# cpsw_9xuss_j7am0_CPSW_NUSS_VBUSP register map
Vendor: Texas Instruments
Registers are 32-bit, read-write, reset 0x0 unless marked. A register's access mark holds for its fields unless they carry their own. Offsets are as the file gives them; [hi:lo] are bit positions; lines under a group give offsets from that group; {n}, {i} and the like mark numbered series; 'fields as' and 'values as' point back to an identical list.

## cpsw_9xuss_j7am0_CPSW_NUSS_VBUSP (part 2 of 3)
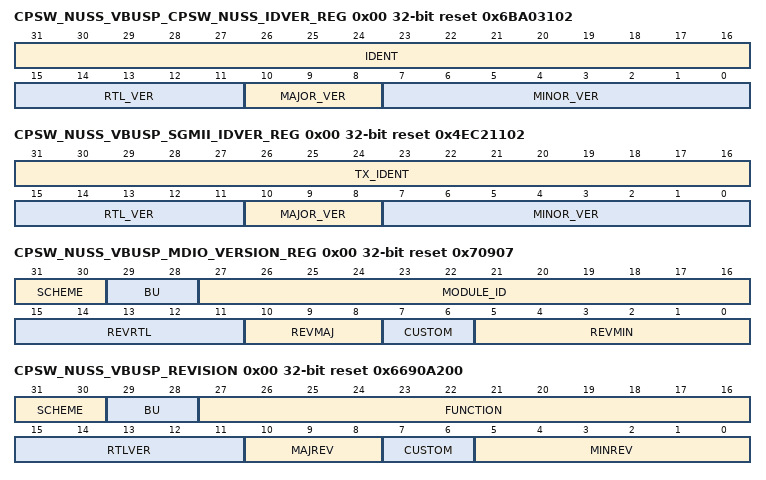
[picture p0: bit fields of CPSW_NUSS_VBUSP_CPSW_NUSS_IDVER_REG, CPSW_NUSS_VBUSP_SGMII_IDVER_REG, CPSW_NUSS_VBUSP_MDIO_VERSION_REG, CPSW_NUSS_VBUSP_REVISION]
0x00 CPSW_NUSS_VBUSP_CPSW_NUSS_IDVER_REG ro reset 0x6BA03102
  [31:16] IDENT — Identification value
  [15:11] RTL_VER — RTL version value
  [10:8] MAJOR_VER — Major version value
  [7:0] MINOR_VER — Minor version value
0x00 CPSW_NUSS_VBUSP_SGMII_IDVER_REG ro reset 0x4EC21102
  [31:16] TX_IDENT — MODULE value
  [15:11] RTL_VER — RTL version value
  [10:8] MAJOR_VER — Major version value
  [7:0] MINOR_VER — Minor version value
0x00 CPSW_NUSS_VBUSP_MDIO_VERSION_REG ro reset 0x70907
  [31:30] SCHEME
  [29:28] BU
  [27:16] MODULE_ID
  [15:11] REVRTL — RTL version
  [10:8] REVMAJ — Major version
  [7:6] CUSTOM — Custom version
  [5:0] REVMIN — Minor version
0x00 CPSW_NUSS_VBUSP_REVISION ro reset 0x6690A200
  [31:30] SCHEME
  [29:28] BU
  [27:16] FUNCTION — Module ID
  [15:11] RTLVER — RTL revisions
  [10:8] MAJREV — Major revision
  [7:6] CUSTOM — Custom revision
  [5:0] MINREV — Minor revision
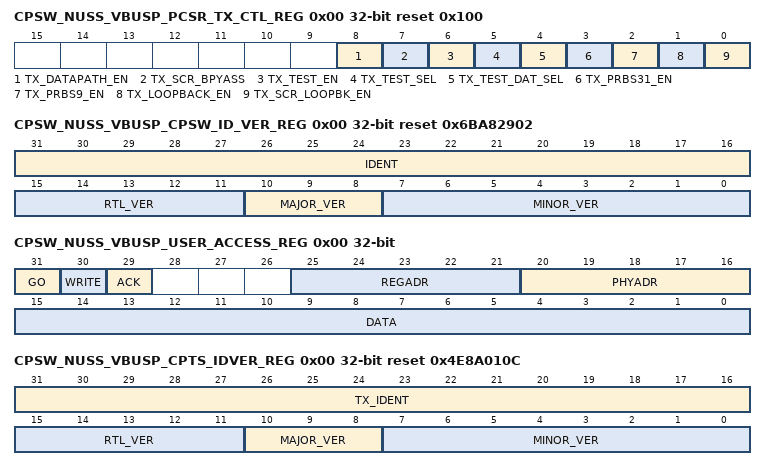
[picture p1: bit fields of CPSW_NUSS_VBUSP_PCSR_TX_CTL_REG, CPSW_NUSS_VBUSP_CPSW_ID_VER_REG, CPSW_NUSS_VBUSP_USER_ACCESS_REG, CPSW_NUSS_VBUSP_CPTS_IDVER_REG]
0x00 CPSW_NUSS_VBUSP_PCSR_TX_CTL_REG reset 0x100
  [8] TX_DATAPATH_EN — PCSR Transmit Datapath Enable
  [7] TX_SCR_BPYASS — PCSR Transmit SCR Bypass
  [6] TX_TEST_EN — PCSR Transmit Test Enable
  [5] TX_TEST_SEL — PCSR Transmit Test Select
  [4] TX_TEST_DAT_SEL — PCSR Transmit Test Data Select
  [3] TX_PRBS31_EN — PCSR Transmit PRBS31 Enable
  [2] TX_PRBS9_EN — PCSR Transmit PRBS9 Enable
  [1] TX_LOOPBACK_EN — PCSR Transmit Loopback Enable
  [0] TX_SCR_LOOPBK_EN — PCSR Transmit SCR Loopback Enable
0x00 CPSW_NUSS_VBUSP_CPSW_ID_VER_REG ro reset 0x6BA82902
  [31:16] IDENT — Identification Value
  [15:11] RTL_VER — RTL Version Value
  [10:8] MAJOR_VER — Major Version Value
  [7:0] MINOR_VER — Minor Version Value
0x00 CPSW_NUSS_VBUSP_USER_ACCESS_REG
  [31] GO
  [30] WRITE
  [29] ACK — Acknowledge
  [25:21] REGADR — Register address
  [20:16] PHYADR — PHY address
  [15:0] DATA — User data
0x00 CPSW_NUSS_VBUSP_PN_RESERVED_REG ro
0x00 CPSW_NUSS_VBUSP_PN_RESERVED_REG ro
0x00 CPSW_NUSS_VBUSP_PN_RESERVED_REG ro
0x00 CPSW_NUSS_VBUSP_PN_RESERVED_REG ro
0x00 CPSW_NUSS_VBUSP_PN_RESERVED_REG ro
0x00 CPSW_NUSS_VBUSP_PN_RESERVED_REG ro
0x00 CPSW_NUSS_VBUSP_PN_RESERVED_REG ro
0x00 CPSW_NUSS_VBUSP_PN_RESERVED_REG ro
0x00 CPSW_NUSS_VBUSP_FETCH_LOC
  [21:0] LOC — RAM Location
0x00 CPSW_NUSS_VBUSP_RXGOODFRAMES
  [31:0] COUNT — Total number of good frames received
0x00 CPSW_NUSS_VBUSP_CPTS_IDVER_REG ro reset 0x4E8A010C
  [31:16] TX_IDENT — Identification value
  [15:11] RTL_VER — RTL version value
  [10:8] MAJOR_VER — Major version value
  [7:0] MINOR_VER — Minor version value
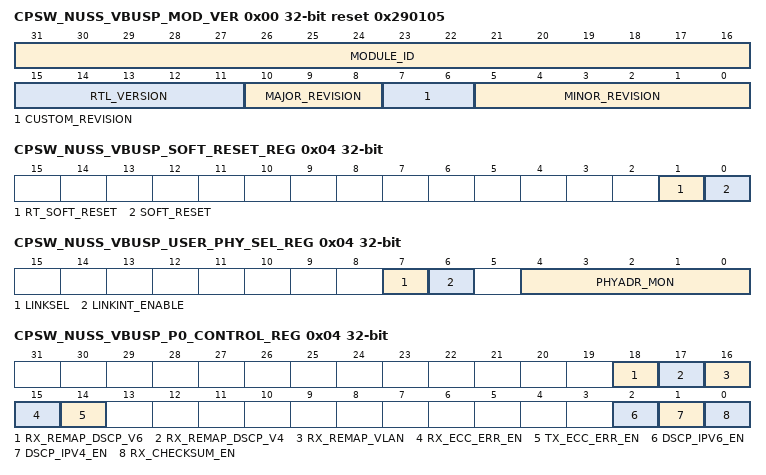
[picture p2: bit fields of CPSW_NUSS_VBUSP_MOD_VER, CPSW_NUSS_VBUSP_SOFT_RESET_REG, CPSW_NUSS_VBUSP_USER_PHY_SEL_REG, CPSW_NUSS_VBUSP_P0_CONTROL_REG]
0x00 CPSW_NUSS_VBUSP_MOD_VER ro reset 0x290105
  [31:16] MODULE_ID — ALE_9g2x1ie module ID.
  [15:11] RTL_VERSION
  [10:8] MAJOR_REVISION
  [7:6] CUSTOM_REVISION
  [5:0] MINOR_REVISION
0x00 CPSW_NUSS_VBUSP_COMP_LOW_REG
  [31:0] COMP_LOW — Time Stamp Generate Function Comparison Low Value
0x00 CPSW_NUSS_VBUSP_COMP_LOW_REG
  [31:0] COMP_LOW — Time Stamp ESTF Generate Function Comparison Low Value
0x04 CPSW_NUSS_VBUSP_SYNCE_COUNT_REG
  [31:0] SYNCE_CNT — Sync E Count Value
0x04 CPSW_NUSS_VBUSP_SOFT_RESET_REG
  [1] RT_SOFT_RESET — Transmit and receive software reset
  [0] SOFT_RESET — Software reset
0x04 CPSW_NUSS_VBUSP_CONTROL_REG access per field reset 0x810000FF
  [31] IDLE ro — MDIO state machine idle
  [30] ENABLE rw — Enable control
  [28:24] HIGHEST_USER_CHANNEL ro
  [20] PREAMBLE rw — Preamble disable
  [19] FAULT rw — Fault indicator
  [18] FAULT_DETECT_ENABLE rw
  [17] INT_TEST_ENABLE rw — Interrupt test enable
  [15:0] CLKDIV rw — Clock divider
0x04 CPSW_NUSS_VBUSP_PCSR_TX_STATUS_REG access not given
  [8] TX_FAULT — PCSR Transmit Fault Hold Register - write 1 to clear (access R/WC)
0x04 CPSW_NUSS_VBUSP_CONTROL_REG
  [31] ECC_CRC_MODE
  [18] EST_ENABLE — Intersperced Express Traffic enable
  [17] IET_ENABLE — Intersperced Express Traffic enable
  [16] EEE_ENABLE — Energy Efficient Ethernet enable
  [15] P0_RX_PASS_CRC_ERR — Port 0 Pass Received CRC errors
  [14] P0_RX_PAD — Port 0 Receive Short Packet Pad
  [13] P0_TX_CRC_REMOVE — Port 0 Transmit CRC remove
  [12] P0_TX_CRC_TYPE — Port 0 Transmit CRC Type
  [n+3] P{n}_PASS_PRI_TAGGED (n=0..8) — Port {n} Pass Priority Tagged
  [2] P0_ENABLE — Port 0 Enable
  [1] VLAN_AWARE — VLAN Aware Mode
  [0] S_CN_SWITCH — VLAN Aware Mode
0x04 CPSW_NUSS_VBUSP_USER_PHY_SEL_REG
  [7] LINKSEL — Link status determination select
  [6] LINKINT_ENABLE — Link change interrupt enable
  [4:0] PHYADR_MON — PHY address whose link status is monitored
0x04 CPSW_NUSS_VBUSP_P0_CONTROL_REG
  [18] RX_REMAP_DSCP_V6 — Port 0 Remap DSCP_V6 Enable
  [17] RX_REMAP_DSCP_V4 — Port 0 Remap DSCP_V4 Enable
  [16] RX_REMAP_VLAN — Port 0 Remap VLAN Enable
  [15] RX_ECC_ERR_EN — Port 0 Receive ECC Error Enable
  [14] TX_ECC_ERR_EN — Port 0 Transmit ECC Error Enable
  [2] DSCP_IPV6_EN — Port 0 IPv6 DSCP enable
  [1] DSCP_IPV4_EN — Port 0 IPv4 DSCP enable
  [0] RX_CHECKSUM_EN — Port 0 Receive Checksum Enable
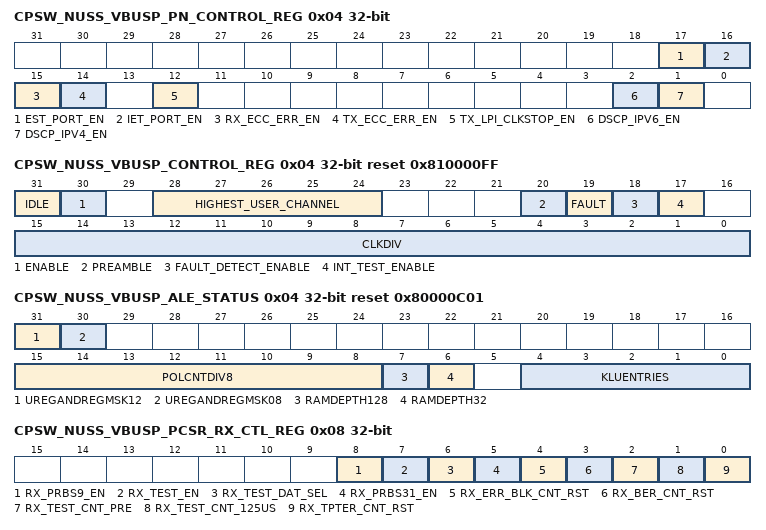
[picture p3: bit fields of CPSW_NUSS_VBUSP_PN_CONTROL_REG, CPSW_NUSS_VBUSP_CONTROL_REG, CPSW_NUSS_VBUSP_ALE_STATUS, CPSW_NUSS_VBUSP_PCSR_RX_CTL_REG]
0x04 CPSW_NUSS_VBUSP_PN_CONTROL_REG
  [17] EST_PORT_EN — EST Port Enable
  [16] IET_PORT_EN — IET Port Enable
  [15] RX_ECC_ERR_EN — Port 0 Receive ECC Error Enable
  [14] TX_ECC_ERR_EN — Port 0 Transmit ECC Error Enable
  [12] TX_LPI_CLKSTOP_EN — Transmit LPI clockstop enable
  [2] DSCP_IPV6_EN — IPv6 DSCP enable
  [1] DSCP_IPV4_EN — IPv4 DSCP enable
0x04 CPSW_NUSS_VBUSP_PN_CONTROL_REG
  fields as CPSW_NUSS_VBUSP_PN_CONTROL_REG
0x04 CPSW_NUSS_VBUSP_PN_CONTROL_REG
  fields as CPSW_NUSS_VBUSP_PN_CONTROL_REG
0x04 CPSW_NUSS_VBUSP_PN_CONTROL_REG
  fields as CPSW_NUSS_VBUSP_PN_CONTROL_REG
0x04 CPSW_NUSS_VBUSP_PN_CONTROL_REG
  fields as CPSW_NUSS_VBUSP_PN_CONTROL_REG
0x04 CPSW_NUSS_VBUSP_PN_CONTROL_REG
  fields as CPSW_NUSS_VBUSP_PN_CONTROL_REG
0x04 CPSW_NUSS_VBUSP_PN_CONTROL_REG
  fields as CPSW_NUSS_VBUSP_PN_CONTROL_REG
0x04 CPSW_NUSS_VBUSP_PN_CONTROL_REG
  fields as CPSW_NUSS_VBUSP_PN_CONTROL_REG
0x04 CPSW_NUSS_VBUSP_RXBROADCASTFRAMES
  [31:0] COUNT — Total number of good broadcast frames received
0x04 CPSW_NUSS_VBUSP_CONTROL_REG reset 0x4
  [31:28] TS_SYNC_SEL — TS_SYNC output timestamp counter bit select
  [17] TS_GENF_CLR_EN — Enable for GENF clear when length is zero
  [16] TS_RX_NO_EVENT — Receive Produces no Events
  [n+7] HW{n}_TS_PUSH_EN (n=1..8) — Hardware push {n} enable
  [7] TS_PPM_DIR — Timestamp PPM Direction
  [6] TS_COMP_TOG — Timestamp Compare Toggle mode: 0=TS_COMP is in non-toggle mode, 1=TS_COMP is in toggle mode
  [5] MODE — Timestamp mode
  [4] SEQUENCE_EN — Sequence Enable
  [3] TSTAMP_EN — Host Receive Timestamp Enable
  [2] TS_COMP_POLARITY
  [1] INT_TEST — Interrupt test
  [0] CPTS_EN — Time sync enable
0x04 CPSW_NUSS_VBUSP_ALE_STATUS ro reset 0x80000C01
  [31] UREGANDREGMSK12 — When set, the unregistered multicast field is a mask versus an index on 12 bit boundary in the ALE table.
  [30] UREGANDREGMSK08 — When set, the unregistered multicast field is a mask versus an index on 8 bit boundary in the ALE table.
  [15:8] POLCNTDIV8 — This is the number of Classifiers the ALE implements divided by 8. A value of 4 indicates 32 policer engines total.
  [7] RAMDEPTH128 — The number of ALE entries per slice of the table when this is set it indicates the depth is 128 if both ramdepth128 and ramdepth32 are zero the depth is 64.
  [6] RAMDEPTH32 — The number of ALE entries per slice of the table when this is set it indicates the depth is 32 if both ramdepth128 and ramdepth32 are zero the depth is 64.
  [4:0] KLUENTRIES — This is the number of table entries total divided by 1024. A value of 1 indicates 1024 table entries. A value of 8 indicates 8192 table entries.
0x04 CPSW_NUSS_VBUSP_COMP_HIGH_REG
  [31:0] COMP_HIGH — Time Stamp Generate Function Comparison High Value
0x04 CPSW_NUSS_VBUSP_COMP_HIGH_REG
  [31:0] COMP_HIGH — Time Stamp ESTF Generate Function Comparison High Value
0x08 CPSW_NUSS_VBUSP_SYNCE_MUX_REG
  [5:0] SYNCE_SEL — Sync E Select Value
0x08 CPSW_NUSS_VBUSP_ALIVE_REG
  [31:0] ALIVE — MDIO alive
0x08 CPSW_NUSS_VBUSP_PCSR_RX_CTL_REG
  [8] RX_PRBS9_EN — PCSR Receive PRBS9 Enable
  [7] RX_TEST_EN — PCSR Receive Test Enable
  [6] RX_TEST_DAT_SEL — PCSR Receive Test Data Select
  [5] RX_PRBS31_EN — PCSR Receive PRBS31 Enable
  [4] RX_ERR_BLK_CNT_RST — PCSR Receive Error Block Count Reset
  [3] RX_BER_CNT_RST — PCSR Receive BER Count Reset
  [2] RX_TEST_CNT_PRE — PCSR Receive Test Count Pre
  [1] RX_TEST_CNT_125US — PCSR Receive Test Count 125us
  [0] RX_TPTER_CNT_RST — PCSR Receive TPTER Count Reset
0x08 CPSW_NUSS_VBUSP_P0_FLOW_ID_OFFSET_REG
  [13:0] VALUE — This value is added to the thread/Flow_ID in CPPI transmit PSI Info Word 0
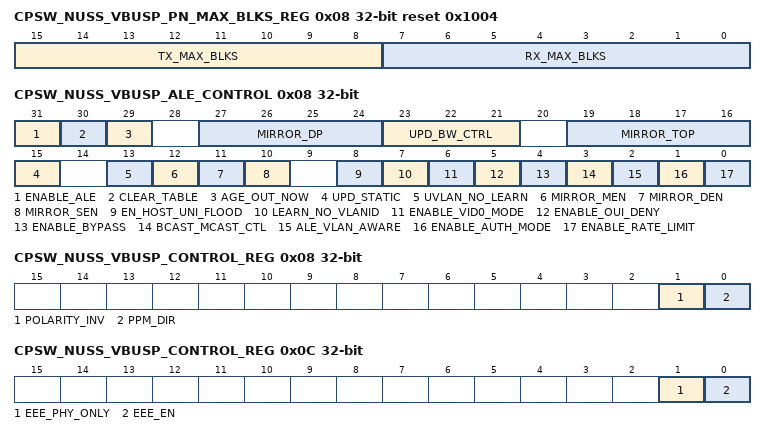
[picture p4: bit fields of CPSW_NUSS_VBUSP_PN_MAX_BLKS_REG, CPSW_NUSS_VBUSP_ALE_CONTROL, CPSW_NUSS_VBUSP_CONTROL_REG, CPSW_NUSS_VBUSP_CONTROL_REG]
0x08 CPSW_NUSS_VBUSP_PN_MAX_BLKS_REG reset 0x1004
  [15:8] TX_MAX_BLKS — Transmit FIFO maximum blocks
  [7:0] RX_MAX_BLKS — Receive FIFO maximum blocks
0x08 CPSW_NUSS_VBUSP_PN_MAX_BLKS_REG reset 0x1004
  fields as CPSW_NUSS_VBUSP_PN_MAX_BLKS_REG
0x08 CPSW_NUSS_VBUSP_PN_MAX_BLKS_REG reset 0x1004
  fields as CPSW_NUSS_VBUSP_PN_MAX_BLKS_REG
0x08 CPSW_NUSS_VBUSP_PN_MAX_BLKS_REG reset 0x1004
  fields as CPSW_NUSS_VBUSP_PN_MAX_BLKS_REG
0x08 CPSW_NUSS_VBUSP_PN_MAX_BLKS_REG reset 0x1004
  fields as CPSW_NUSS_VBUSP_PN_MAX_BLKS_REG
0x08 CPSW_NUSS_VBUSP_PN_MAX_BLKS_REG reset 0x1004
  fields as CPSW_NUSS_VBUSP_PN_MAX_BLKS_REG
0x08 CPSW_NUSS_VBUSP_PN_MAX_BLKS_REG reset 0x1004
  fields as CPSW_NUSS_VBUSP_PN_MAX_BLKS_REG
0x08 CPSW_NUSS_VBUSP_PN_MAX_BLKS_REG reset 0x1004
  fields as CPSW_NUSS_VBUSP_PN_MAX_BLKS_REG
0x08 CPSW_NUSS_VBUSP_RXMULTICASTFRAMES
  [31:0] COUNT — Total number of good multicast frames received
0x08 CPSW_NUSS_VBUSP_RFTCLK_SEL_REG
  [4:0] RFTCLK_SEL — Reference clock select
0x08 CPSW_NUSS_VBUSP_ALE_CONTROL
  [31] ENABLE_ALE — Enable ALE 0 - Drop all packets 1 - Enable ALE packet processing
  [30] CLEAR_TABLE — Clear ALE address table - Setting this bit causes the ALE hardware to write all table bit values to zero. Software must perform a clear table operation as part of the ALE setup/configuration process. Setting this bit causes all ALE accesses to be held up for 64 clocks while the clear is performed. Access to all ALE registers will be blocked (wait states) until the 64 clocks have completed. This bit cannot be read as one because the read is blocked until the clear table is completed at which time this bit is cleared to zero.
  [29] AGE_OUT_NOW — Age Out Address Table Now - Setting this bit causes the ALE hardware to remove (free up) any ageable table entry that does not have a set touch bit. This bit is cleared when the age out process has completed. This bit may be read. The age out process takes four times the number of table entries clock cycles (4096 cycles for 1K addresses) best case (no ale packet processing during ageout) and sixty five times the number of table entries clock cycles (66560 cycles for 1K addresses) absolute worst case.
  [27:24] MIRROR_DP — Mirror Destination Port - This field defines the port to which destination traffic destined will be duplicated. That is all traffic that is forwarded to this port will also be mirrored to the ~imirror_top port.
  [23:21] UPD_BW_CTRL — The ~iupd_bw_ctrl field allows for up to 8 times the rate in which adds, updates, touches, writes, and aging updates can occur. At frequencies of 350Mhz, the table update rate should be at it lowest or 5 Million updates per second. When operating the switch core at frequencies or above, the ~iupd_bw_ctrl can be programmed more aggressive. If the ~iupd_bw_ctrl is set but the frequency of the switch subsystem is below the associated value, ALE will drop packets due to insufficient time to complete lookup under high traffic loads. 0 - 350Mhz, 5M 1 - 359Mhz, 11M 2 - 367Mhz, 16M 3 - 375Mhz, 22M 4 - 384Mhz, 28M 5 - 392Mhz, 34M 6 - 400Mhz, 39M 7 - 409Mhz, 45M
  [19:16] MIRROR_TOP — Mirror To Port - This field defines the destination port for the mirror traffic. If the traffic is received or transmitted on the mirror destination port it will not be duplicated. Traffic defined as mirror traffic only may be dropped by the switch due to congestion.
  [15] UPD_STATIC — Update Static Entries - A static Entry is an entry that is not agable. When clear this bit will prevent any static entry (agable bit clear) from being updated due to port change. When set it allows static entries (agable bit clear) to update the source port if required. This bit should normally be '0' for most switch configurations.
  [13] UVLAN_NO_LEARN — Unknown VLAN No Learn - This field when set will prevent source addresses of unknown VLAN IDs from being automatically added into the look up table if learning is enabled.
  [12] MIRROR_MEN — Mirror Match Entry Enable - This field enables the match mirror option. When this bit is set any traffic whose destination, source, VLAN or OUI matches the ~imirror_midx entry index will have that traffic also sent to the ~imirror_top port.
  [11] MIRROR_DEN — Mirror Destination Port Enable - This field enables the destination port mirror option. When this bit is set any traffic destined for the ~imirror_dp port will have its transmit traffic also sent to the ~imirror_top port.
  [10] MIRROR_SEN — Mirror Source Port Enable - This field enables the source port mirror option. When this bit is set any port with the ~ipX_mirror_sp set in the ALE Port Control registers set will have its received traffic also sent to the ~imirror_top port.
  [8] EN_HOST_UNI_FLOOD — Unknown unicast packets flood to host 0 - unknown unicast packets are not sent to the host 1 - unknown unicast packets flood to host port as well as other ports
  [7] LEARN_NO_VLANID — Learn No VID - 0 - VID is learned with the source address 1 - VID is not learned with the source address (source address is not tied to VID). Determines the entry type.
  [6] ENABLE_VID0_MODE — Enable VLAN ID = 0 Mode 0 - Process the priority tagged packet with VID = PORT_VLAN[11:0]. 1 - Process the priority tagged packet with VID = 0.
  [5] ENABLE_OUI_DENY — Enable OUI Deny Mode - When set, any packet with a non-matching OUI source address will be dropped to the host unless the packet destination address matches a supervisory destination address table entry. When cleared, any packet source address matching an OUI address table entry will be dropped to the host unless the destination address matches with a supervisory destination address table entry.
  [4] ENABLE_BYPASS — ALE Bypass - When set, packets received on non-host ports are sent to the host. It is expected that packets from the host are directed to the particular port. 0 - no bypass 1 - bypass the ALE
  [3] BCAST_MCAST_CTL — Rate Limit Transmit mode 0 - Broadcast and multicast rate limit counters are received port based 1 - Broadcast and multicast rate limit counters are transmit port based
  [2] ALE_VLAN_AWARE — ALE VLAN Aware - Determines how traffic is forwarded using VLAN rules. 0 - Simple switch rules, packets forwarded to all ports for unknown destinations. 1 - VLAN Aware rules, packets forwarded based on VLAN members
  [1] ENABLE_AUTH_MODE — Enable MAC Authorization Mode - Mac authorization mode requires that all table entries be made by the host software. There is no auto learning of addresses in authorization mode and the packet will be dropped if the source address is not found (and the destination address is not a multicast address with the super table entry bit set). 0 - The ALE is not in MAC authorization mode 1 - The ALE is in MAC authorization mode
  [0] ENABLE_RATE_LIMIT — Enable Broadcast and Multicast Rate Limit 0 - Broadcast/Multicast rates not limited 1 - Broadcast/Multicast packet reception limited to the port control register rate limit fields.
0x08 CPSW_NUSS_VBUSP_CONTROL_REG
  [1] POLARITY_INV — Time Stamp Generate Function Polarity Invert
  [0] PPM_DIR — Time Stamp Generate Function PPM Direction
0x08 CPSW_NUSS_VBUSP_CONTROL_REG
  [1] POLARITY_INV — Time Stamp ESTF Generate Function Polarity Invert
  [0] PPM_DIR — Time Stamp ESTF Generate Function PPM Direction
0x0C CPSW_NUSS_VBUSP_CONTROL_REG
  [1] EEE_PHY_ONLY — Energy Efficient Enable Phy Only Mode: 0=The low power indicate state includes gating off the CPPI_GCLK to the CPSW, 1=The low power indicate state does not gate the clock to the CPSW
  [0] EEE_EN — Energy Efficient Ethernet Enable: 0=EEE is disabled, 1=EEE is enabled
0x0C CPSW_NUSS_VBUSP_LINK_REG ro
  [31:0] LINK — MDIO link state
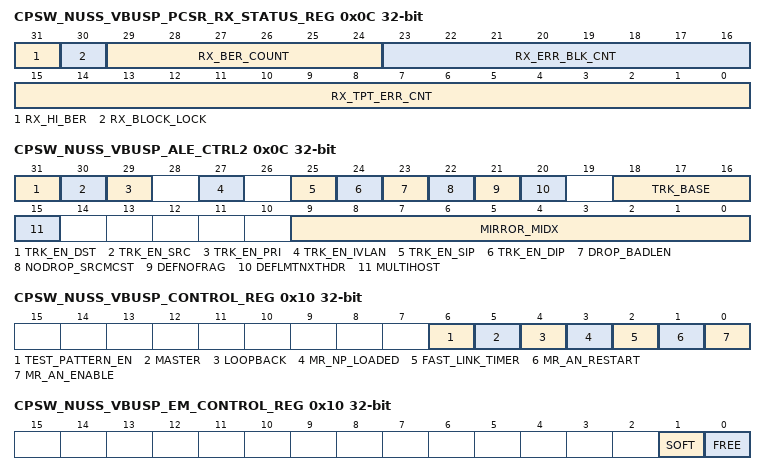
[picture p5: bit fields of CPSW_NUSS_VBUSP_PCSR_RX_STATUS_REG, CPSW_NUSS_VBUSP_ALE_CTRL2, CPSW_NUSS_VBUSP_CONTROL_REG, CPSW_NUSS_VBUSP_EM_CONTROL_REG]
0x0C CPSW_NUSS_VBUSP_PCSR_RX_STATUS_REG ro
  [31] RX_HI_BER — PCSR Receive High BER
  [30] RX_BLOCK_LOCK — PCSR Receive Block Lock
  [29:24] RX_BER_COUNT — PCSR Receive BER Count
  [23:16] RX_ERR_BLK_CNT — PCSR Error Block Count
  [15:0] RX_TPT_ERR_CNT — PCSR TPT Error Count
0x0C CPSW_NUSS_VBUSP_RXPAUSEFRAMES
  [31:0] COUNT — Total number of pause frames received
0x0C CPSW_NUSS_VBUSP_TS_PUSH_REG wo
  [0] TS_PUSH — Time stamp event push
0x0C CPSW_NUSS_VBUSP_ALE_CTRL2
  [31] TRK_EN_DST — Trunk Enable Destination Address - This field enables the destination MAC address to be used with the hash function G(X) = 1 + X + X^3 and affect the trunk port transmit link determination.
  [30] TRK_EN_SRC — Trunk Enable Source Address - This field enables the source MAC address to be used with the hash function G(X) = 1 + X + X^3 and affect the trunk port transmit link determination.
  [29] TRK_EN_PRI — Trunk Enable Priority - This field enables the VLAN Priority bits to be used with the hash function G(X) = 1 + X + X^3 and affect the trunk port transmit link determination. In the event that DSCP mapping is enabled and there is no VLAN the DSCP priority will be used. For all other non IP frames without VLAN the port default priority is used.
  [27] TRK_EN_IVLAN — Trunk Enable Inner VLAN - This field enables the inner VLAN ID value (C-VLANID) to be used with the hash function G(X) = 1 + X + X^3 and affect the trunk port transmit link determination.
  [25] TRK_EN_SIP — Trunk Enable Source IP Address - This field enables the source IP address to be used with the hash function G(X) = 1 + X + X^3 and affect the trunk port transmit link determination. This feature supports No tag, Priority tagged, VLAN tagged, Q-in-Q double tagging for both IPV6 and IPV4.
  [24] TRK_EN_DIP — Trunk Enable Destination IP Address - This field enables the destination IP address to be used with the hash function G(X) = 1 + X + X^3 and affect the trunk port transmit link determination. This feature supports No tag, Priority tagged, VLAN tagged, Q-in-Q double tagging for both IPV6 and IPV4.
  [23] DROP_BADLEN — Drop Bad Length will drop any packet that the 802.3 length field is larger than the packet. Ethertypes 0-1500 are 802.3 lengths, all others are Ether types.
  [22] NODROP_SRCMCST — No Drop Source Multicast will disable the dropping of any source address with the multicast bit set.
  [21] DEFNOFRAG — Default No Frag field will cause an IPv4 fragmented packet to be dropped if a VLAN entry is not found.
  [20] DEFLMTNXTHDR — Default limit next header field will cause an IPv4 protocol or IPv6 next header packet to be dropped if a VLAN entry is not found and the protocol or next header does not match the ~iALE_NXT_HDR register values.
  [18:16] TRK_BASE — Trunk Base - This field is the hash formula starting value. Changing this value will cause the packet distribution on trunk ports to be changed. If all the ~itrk_en_dst, ~itrk_en_src, ~itrk_en_pri and ~itrk_en_vlan are '0', this value is used as the distribution index. That is a '0' will select the 1st bit of an 'N' link trunk, a '1' will select the second, etc. Below is the distribution across the trunk links. The first number in the ~iitalic sequence indicates the traffic is sent to the lowest numbered port of a trunk group. For example if you have a 3 port trunk, the hash result 0 will go to the base port (0), hash result 1 will go to the highest port of the trunk group (2), hash result 2 will go to the middle port (1), etc. 1 - ~i00000000 2 - ~i01010101 3 - ~i02102102 4 - ~i03210321
  [15] MULTIHOST — The ~multihost allows host traffic to be sent bact to the host if the DA is market for the host port.
  [9:0] MIRROR_MIDX — Mirror Index - This field is the ALE lookup table entry index that when a match occurs will cause this traffic to be mirrored to the ~imirror_top port. That is any VLAN, ONU or address with or withou VLAN can be selected for traffic mirroring.
0x0C CPSW_NUSS_VBUSP_LENGTH_REG
  [31:0] LENGTH — Time Stamp Generate Function Length Value
0x0C CPSW_NUSS_VBUSP_LENGTH_REG
  [31:0] LENGTH — Time Stamp ESTF Generate Function Length Value
0x10 CPSW_NUSS_VBUSP_SGMII_NON_FIBER_MODE_REG reset 0xFF
  [7:0] SGMII_NON_FIBER_MODE — This register bit goes to the CPSGMII mode input only
0x10 CPSW_NUSS_VBUSP_CONTROL_REG
  [6] TEST_PATTERN_EN — Test pattern enable
  [5] MASTER — Master mode
  [4] LOOPBACK — Loopback mode
  [3] MR_NP_LOADED — Next page loaded
  [2] FAST_LINK_TIMER
  [1] MR_AN_RESTART — Auto-negotiation restart
  [0] MR_AN_ENABLE — Auto-negotiation enable
0x10 CPSW_NUSS_VBUSP_LINK_INT_RAW_REG
  [1:0] LINKINTRAW — MDIO link change event raw value
0x10 CPSW_NUSS_VBUSP_eoi_reg
  [7:0] EOI_VECTOR — End of Interrupt Vector
0x10 CPSW_NUSS_VBUSP_PCSR_SEED_A_LO_REG
  [31:0] SEED_A_LO — PCSR Seed A Low
0x10 CPSW_NUSS_VBUSP_EM_CONTROL_REG
  [1] SOFT — Emulation Soft Bit
  [0] FREE — Emulation Free Bit
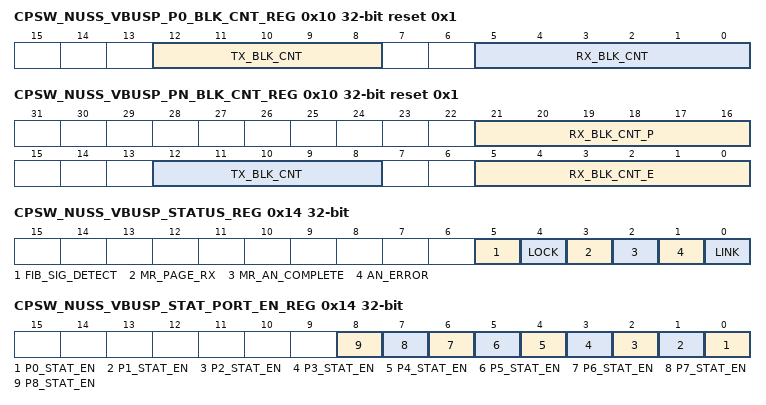
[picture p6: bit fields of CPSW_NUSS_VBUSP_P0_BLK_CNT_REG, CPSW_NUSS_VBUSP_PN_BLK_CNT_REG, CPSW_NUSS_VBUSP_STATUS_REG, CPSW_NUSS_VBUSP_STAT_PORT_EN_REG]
0x10 CPSW_NUSS_VBUSP_P0_BLK_CNT_REG ro reset 0x1
  [12:8] TX_BLK_CNT — Port 0 Transmit Block Count Usage
  [5:0] RX_BLK_CNT — Port 0 Receive Block Count Usage
0x10 CPSW_NUSS_VBUSP_PN_BLK_CNT_REG ro reset 0x1
  [21:16] RX_BLK_CNT_P — Receive Prempt Queue Block Count Usage
  [12:8] TX_BLK_CNT — Transmit Block Count Usage
  [5:0] RX_BLK_CNT_E — Receive Block Count Usage
0x10 CPSW_NUSS_VBUSP_PN_BLK_CNT_REG ro reset 0x1
  fields as CPSW_NUSS_VBUSP_PN_BLK_CNT_REG
0x10 CPSW_NUSS_VBUSP_PN_BLK_CNT_REG ro reset 0x1
  fields as CPSW_NUSS_VBUSP_PN_BLK_CNT_REG
0x10 CPSW_NUSS_VBUSP_PN_BLK_CNT_REG ro reset 0x1
  fields as CPSW_NUSS_VBUSP_PN_BLK_CNT_REG
0x10 CPSW_NUSS_VBUSP_PN_BLK_CNT_REG ro reset 0x1
  fields as CPSW_NUSS_VBUSP_PN_BLK_CNT_REG
0x10 CPSW_NUSS_VBUSP_PN_BLK_CNT_REG ro reset 0x1
  fields as CPSW_NUSS_VBUSP_PN_BLK_CNT_REG
0x10 CPSW_NUSS_VBUSP_PN_BLK_CNT_REG ro reset 0x1
  fields as CPSW_NUSS_VBUSP_PN_BLK_CNT_REG
0x10 CPSW_NUSS_VBUSP_PN_BLK_CNT_REG ro reset 0x1
  fields as CPSW_NUSS_VBUSP_PN_BLK_CNT_REG
0x10 CPSW_NUSS_VBUSP_RXCRCERRORS
  [31:0] COUNT — Total number of CRC errors frames received
0x10 CPSW_NUSS_VBUSP_TS_LOAD_LOW_VAL_REG
  [31:0] TS_LOAD_VAL — Time stamp load low value
0x10 CPSW_NUSS_VBUSP_ALE_PRESCALE
  [19:0] ALE_PRESCALE — ALE Prescale - The input clock is divided by this value for use in the multicast/broadcast rate limiters. The minimum operating value is 0x10. The prescaler is off when the value is zero.
0x10 CPSW_NUSS_VBUSP_PPM_LOW_REG
  [31:0] PPM_LOW — Time Stamp Generate Function PPM Low Value
0x10 CPSW_NUSS_VBUSP_PPM_LOW_REG
  [31:0] PPM_LOW — Time Stamp ESTF Generate Function PPM Low Value
0x14 CPSW_NUSS_VBUSP_SERDES_RESET_ISO_REG
  [7:0] SERDES_RESET_ISO — These bits control whether the SERDES ignores the hard reset for isolation or not
0x14 CPSW_NUSS_VBUSP_STATUS_REG ro
  [5] FIB_SIG_DETECT — Fiber signal detect
  [4] LOCK
  [3] MR_PAGE_RX — Next page received
  [2] MR_AN_COMPLETE — Auto-negotiation complete
  [1] AN_ERROR — Auto-negotiation error
  [0] LINK — Link indicator
0x14 CPSW_NUSS_VBUSP_LINK_INT_MASKED_REG
  [1:0] LINKINTMASKED — MDIO link change interrupt masked value
0x14 CPSW_NUSS_VBUSP_intr_vector_reg ro
  [31:0] INTR_VECTOR — Interrupt Vector Register
0x14 CPSW_NUSS_VBUSP_PCSR_SEED_A_HI_REG
  [25:0] SEED_A_HI — PCSR Seed A High
0x14 CPSW_NUSS_VBUSP_STAT_PORT_EN_REG
  [n] P{n}_STAT_EN (n=0..8) — Port {n} Statistics Enable
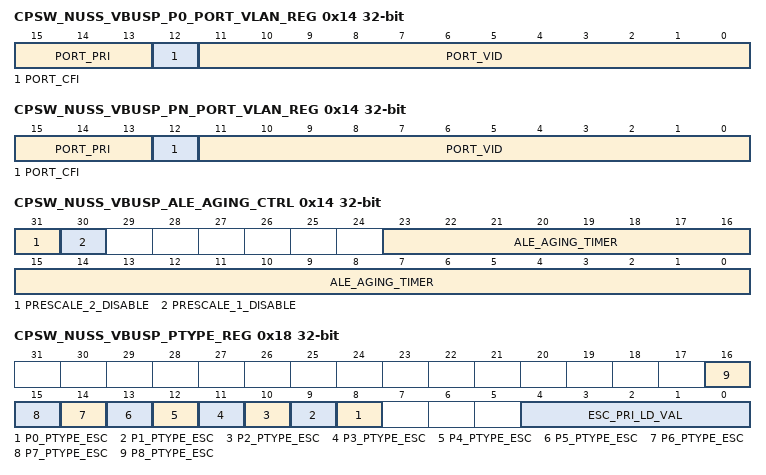
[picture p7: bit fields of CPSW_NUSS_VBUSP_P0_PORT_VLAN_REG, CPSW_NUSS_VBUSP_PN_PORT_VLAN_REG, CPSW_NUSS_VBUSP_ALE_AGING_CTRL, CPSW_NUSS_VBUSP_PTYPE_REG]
0x14 CPSW_NUSS_VBUSP_P0_PORT_VLAN_REG
  [15:13] PORT_PRI — Port VLAN Priority
  [12] PORT_CFI — Port CFI bit
  [11:0] PORT_VID — Port VLAN ID
0x14 CPSW_NUSS_VBUSP_PN_PORT_VLAN_REG
  fields as CPSW_NUSS_VBUSP_P0_PORT_VLAN_REG
0x14 CPSW_NUSS_VBUSP_PN_PORT_VLAN_REG
  fields as CPSW_NUSS_VBUSP_P0_PORT_VLAN_REG
0x14 CPSW_NUSS_VBUSP_PN_PORT_VLAN_REG
  fields as CPSW_NUSS_VBUSP_P0_PORT_VLAN_REG
0x14 CPSW_NUSS_VBUSP_PN_PORT_VLAN_REG
  fields as CPSW_NUSS_VBUSP_P0_PORT_VLAN_REG
0x14 CPSW_NUSS_VBUSP_PN_PORT_VLAN_REG
  fields as CPSW_NUSS_VBUSP_P0_PORT_VLAN_REG
0x14 CPSW_NUSS_VBUSP_PN_PORT_VLAN_REG
  fields as CPSW_NUSS_VBUSP_P0_PORT_VLAN_REG
0x14 CPSW_NUSS_VBUSP_PN_PORT_VLAN_REG
  fields as CPSW_NUSS_VBUSP_P0_PORT_VLAN_REG
0x14 CPSW_NUSS_VBUSP_PN_PORT_VLAN_REG
  fields as CPSW_NUSS_VBUSP_P0_PORT_VLAN_REG
0x14 CPSW_NUSS_VBUSP_RXALIGNCODEERRORS
  [31:0] COUNT — Total number of alignment/code errors received
0x14 CPSW_NUSS_VBUSP_TS_LOAD_EN_REG wo
  [0] TS_LOAD_EN — Time stamp load enable
0x14 CPSW_NUSS_VBUSP_ALE_AGING_CTRL
  [31] PRESCALE_2_DISABLE — ALE Prescaler 2 Disable - When set will divide the aging interval by 1000. This bit is designed for device verification and should not be used in production software. Combination of PreScale1Disable and PreScale2Disable will divide the aging interval by 1,000,000 for test purposes.
  [30] PRESCALE_1_DISABLE — ALE Prescaler 1 Disable - When set will divide the aging interval by 1000. This bit is designed for device verification and should not be used in production software. Combination of PreScale1Disable and PreScale2Disable will divide the aging interval by 1,000,000 for test purposes.
  [23:0] ALE_AGING_TIMER — ALE Aging Timer - This field specifies the number of clock cycles times 1,000,000 between aging operations.
0x14 CPSW_NUSS_VBUSP_PPM_HIGH_REG
  [9:0] PPM_HIGH — Time Stamp Generate Function PPM High Value
0x14 CPSW_NUSS_VBUSP_PPM_HIGH_REG
  [9:0] PPM_HIGH — Time Stamp ESTF Generate Function PPM High Value
0x18 CPSW_NUSS_VBUSP_MR_ADV_ABILITY_REG
  [15:0] MR_ADV_ABILITY — Advertised ability
0x18 CPSW_NUSS_VBUSP_LINK_INT_MASK_SET_REG
  [0] LINKINTMASKSET — MDIO link interrupt mask set
0x18 CPSW_NUSS_VBUSP_PCSR_SEED_B_LO_REG
  [31:0] SEED_B_LO — PCSR Seed B Low
0x18 CPSW_NUSS_VBUSP_PTYPE_REG
  [n+8] P{n}_PTYPE_ESC (n=0..8) — Port {n} Priority Type Escalate
  [4:0] ESC_PRI_LD_VAL — Escalate Priority Load Value
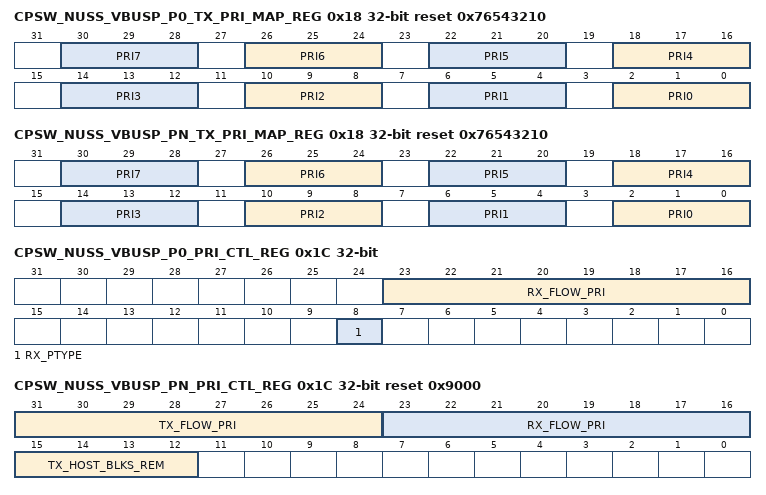
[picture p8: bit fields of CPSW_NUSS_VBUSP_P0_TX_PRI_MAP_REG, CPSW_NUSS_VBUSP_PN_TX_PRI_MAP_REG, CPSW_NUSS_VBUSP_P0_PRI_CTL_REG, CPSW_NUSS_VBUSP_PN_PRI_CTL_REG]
0x18 CPSW_NUSS_VBUSP_P0_TX_PRI_MAP_REG reset 0x76543210
  [4n+2:4n] PRI{n} (n=0..7) — Priority {n}
0x18 CPSW_NUSS_VBUSP_PN_TX_PRI_MAP_REG reset 0x76543210
  [4n+2:4n] PRI{n} (n=0..7) — Priority {n}
0x18 CPSW_NUSS_VBUSP_PN_TX_PRI_MAP_REG reset 0x76543210
  [4n+2:4n] PRI{n} (n=0..7) — Priority {n}
0x18 CPSW_NUSS_VBUSP_PN_TX_PRI_MAP_REG reset 0x76543210
  [4n+2:4n] PRI{n} (n=0..7) — Priority {n}
0x18 CPSW_NUSS_VBUSP_PN_TX_PRI_MAP_REG reset 0x76543210
  [4n+2:4n] PRI{n} (n=0..7) — Priority {n}
0x18 CPSW_NUSS_VBUSP_PN_TX_PRI_MAP_REG reset 0x76543210
  [4n+2:4n] PRI{n} (n=0..7) — Priority {n}
0x18 CPSW_NUSS_VBUSP_PN_TX_PRI_MAP_REG reset 0x76543210
  [4n+2:4n] PRI{n} (n=0..7) — Priority {n}
0x18 CPSW_NUSS_VBUSP_PN_TX_PRI_MAP_REG reset 0x76543210
  [4n+2:4n] PRI{n} (n=0..7) — Priority {n}
0x18 CPSW_NUSS_VBUSP_PN_TX_PRI_MAP_REG reset 0x76543210
  [4n+2:4n] PRI{n} (n=0..7) — Priority {n}
0x18 CPSW_NUSS_VBUSP_RXOVERSIZEDFRAMES
  [31:0] COUNT — Total number of oversized frames received
0x18 CPSW_NUSS_VBUSP_TS_COMP_LOW_VAL_REG
  [31:0] TS_COMP_VAL — Time stamp comparison low value
0x18 CPSW_NUSS_VBUSP_NUDGE_REG
  [7:0] NUDGE — Time Stamp Generate Function Nudge Value
0x18 CPSW_NUSS_VBUSP_NUDGE_REG
  [7:0] NUDGE — Time Stamp ESTF Generate Function Nudge Value
0x1C CPSW_NUSS_VBUSP_SUBSSYSTEM_STATUS_REG ro
  [0] EEE_CLKSTOP_ACK — Energy Efficient Ethernet clockstop acknowledge from CPSW
0x1C CPSW_NUSS_VBUSP_MR_NP_TX_REG
  [15:0] MR_NP_TX — Next page transmit
0x1C CPSW_NUSS_VBUSP_LINK_INT_MASK_CLEAR_REG
  [0] LINKINTMASKCLR — MDIO link interrupt mask clear
0x1C CPSW_NUSS_VBUSP_PCSR_SEED_B_HI_REG
  [25:0] SEED_B_HI — PCSR Seed B High
0x1C CPSW_NUSS_VBUSP_SOFT_IDLE_REG
  [0] SOFT_IDLE — Software Idle
0x1C CPSW_NUSS_VBUSP_P0_PRI_CTL_REG
  [23:16] RX_FLOW_PRI — Receive Priority Based Flow Control Enable (per priority)
  [8] RX_PTYPE — Receive Priority Type
0x1C CPSW_NUSS_VBUSP_PN_PRI_CTL_REG reset 0x9000
  [31:24] TX_FLOW_PRI — Transmit Priority Based Flow Control Enable (per priority)
  [23:16] RX_FLOW_PRI — Receive Priority Based Flow Control Enable (per priority)
  [15:12] TX_HOST_BLKS_REM — Transmit FIFO Blocks that must be free before a non rate-limited CPPI Port 0 receive thread can begin sending a packet
0x1C CPSW_NUSS_VBUSP_PN_PRI_CTL_REG reset 0x9000
  fields as CPSW_NUSS_VBUSP_PN_PRI_CTL_REG
0x1C CPSW_NUSS_VBUSP_PN_PRI_CTL_REG reset 0x9000
  fields as CPSW_NUSS_VBUSP_PN_PRI_CTL_REG
0x1C CPSW_NUSS_VBUSP_PN_PRI_CTL_REG reset 0x9000
  fields as CPSW_NUSS_VBUSP_PN_PRI_CTL_REG
0x1C CPSW_NUSS_VBUSP_PN_PRI_CTL_REG reset 0x9000
  fields as CPSW_NUSS_VBUSP_PN_PRI_CTL_REG
0x1C CPSW_NUSS_VBUSP_PN_PRI_CTL_REG reset 0x9000
  fields as CPSW_NUSS_VBUSP_PN_PRI_CTL_REG
0x1C CPSW_NUSS_VBUSP_PN_PRI_CTL_REG reset 0x9000
  fields as CPSW_NUSS_VBUSP_PN_PRI_CTL_REG
0x1C CPSW_NUSS_VBUSP_PN_PRI_CTL_REG reset 0x9000
  fields as CPSW_NUSS_VBUSP_PN_PRI_CTL_REG
0x1C CPSW_NUSS_VBUSP_RXJABBERFRAMES
  [31:0] COUNT — Total number of jabber frames received
0x1C CPSW_NUSS_VBUSP_TS_COMP_LEN_REG
  [31:0] TS_COMP_LENGTH — Time stamp comparison length
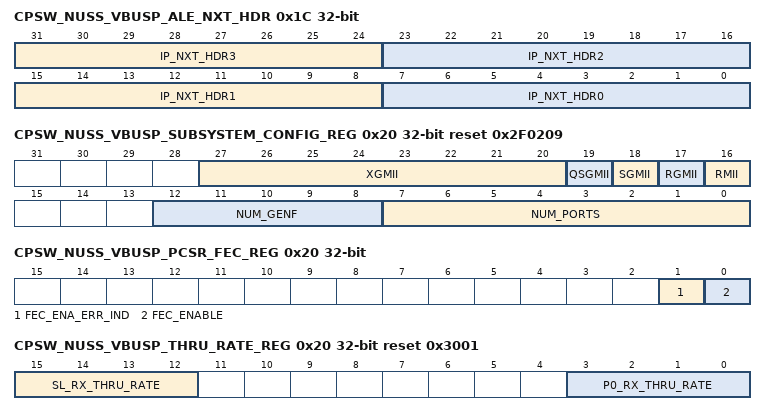
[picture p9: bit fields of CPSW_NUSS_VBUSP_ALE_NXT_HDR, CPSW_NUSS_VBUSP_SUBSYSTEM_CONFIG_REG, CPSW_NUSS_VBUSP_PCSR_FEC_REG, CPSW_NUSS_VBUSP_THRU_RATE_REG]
0x1C CPSW_NUSS_VBUSP_ALE_NXT_HDR
  [31:24] IP_NXT_HDR3 — The ~iip_nxt_hdr3 is the forth protocol or next header compared when enabled.
  [23:16] IP_NXT_HDR2 — The ~iip_nxt_hdr2 is the third protocol or next header compared when enabled.
  [15:8] IP_NXT_HDR1 — The ~iip_nxt_hdr1 is the second protocol or next header compared when enabled.
  [7:0] IP_NXT_HDR0 — The ~iip_nxt_hdr0 is the first protocol or next header compared when enabled.
0x20 CPSW_NUSS_VBUSP_SUBSYSTEM_CONFIG_REG ro reset 0x2F0209
  [27:20] XGMII — The Number of XGMII Ports included in the CPSW_NUSS
  [19] QSGMII — QSGMII is included in the CPSW_NUSS
  [18] SGMII — SGMII is included in the CPSW_NUSS
  [17] RGMII — RGMII is included in the CPSW_NUSS
  [16] RMII — RMII is included in the CPSW_NUSS
  [12:8] NUM_GENF — The number of CPTS GENF outputs
  [7:0] NUM_PORTS — The total number of ports including the host port 0
0x20 CPSW_NUSS_VBUSP_MR_LP_ADV_ABILITY_REG ro
  [15:0] MR_LP_ADV_ABILITY — Link partner advertised ability
0x20 CPSW_NUSS_VBUSP_USER_INT_RAW_REG
  [1:0] USERINTRAW — User interrupt raw
0x20 CPSW_NUSS_VBUSP_PCSR_FEC_REG
  [1] FEC_ENA_ERR_IND — PCSR FEC ENA Error Ind
  [0] FEC_ENABLE — PCSR FEC Enable
0x20 CPSW_NUSS_VBUSP_THRU_RATE_REG reset 0x3001
  [15:12] SL_RX_THRU_RATE — Switch FIFO receive through rate
  [3:0] P0_RX_THRU_RATE — CPPI FIFO receive through rate
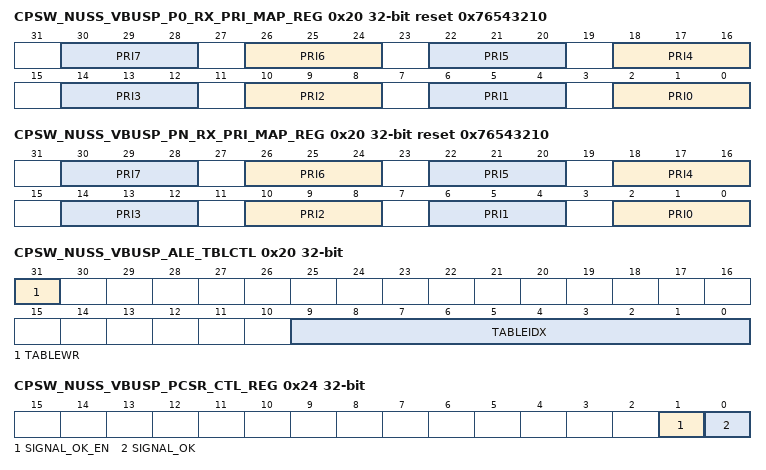
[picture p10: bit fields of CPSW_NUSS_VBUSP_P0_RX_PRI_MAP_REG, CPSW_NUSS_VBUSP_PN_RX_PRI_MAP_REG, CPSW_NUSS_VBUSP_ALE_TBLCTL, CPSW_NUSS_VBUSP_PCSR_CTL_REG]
0x20 CPSW_NUSS_VBUSP_P0_RX_PRI_MAP_REG reset 0x76543210
  [4n+2:4n] PRI{n} (n=0..7) — Priority {n}
0x20 CPSW_NUSS_VBUSP_PN_RX_PRI_MAP_REG reset 0x76543210
  [4n+2:4n] PRI{n} (n=0..7) — Priority {n}
0x20 CPSW_NUSS_VBUSP_PN_RX_PRI_MAP_REG reset 0x76543210
  [4n+2:4n] PRI{n} (n=0..7) — Priority {n}
0x20 CPSW_NUSS_VBUSP_PN_RX_PRI_MAP_REG reset 0x76543210
  [4n+2:4n] PRI{n} (n=0..7) — Priority {n}
0x20 CPSW_NUSS_VBUSP_PN_RX_PRI_MAP_REG reset 0x76543210
  [4n+2:4n] PRI{n} (n=0..7) — Priority {n}
0x20 CPSW_NUSS_VBUSP_PN_RX_PRI_MAP_REG reset 0x76543210
  [4n+2:4n] PRI{n} (n=0..7) — Priority {n}
0x20 CPSW_NUSS_VBUSP_PN_RX_PRI_MAP_REG reset 0x76543210
  [4n+2:4n] PRI{n} (n=0..7) — Priority {n}
0x20 CPSW_NUSS_VBUSP_PN_RX_PRI_MAP_REG reset 0x76543210
  [4n+2:4n] PRI{n} (n=0..7) — Priority {n}
0x20 CPSW_NUSS_VBUSP_PN_RX_PRI_MAP_REG reset 0x76543210
  [4n+2:4n] PRI{n} (n=0..7) — Priority {n}
0x20 CPSW_NUSS_VBUSP_RXUNDERSIZEDFRAMES
  [31:0] COUNT — Total number of undersized frames received
0x20 CPSW_NUSS_VBUSP_INTSTAT_RAW_REG
  [0] TS_PEND_RAW — TS_PEND_RAW int read (before enable)
0x20 CPSW_NUSS_VBUSP_ALE_TBLCTL
  [31] TABLEWR — Table Write - This bit is used to write the table words to the lookup table. 0 - Table Read Operation is performed. The contents of the ~b TABLEIDX entry will be read into the ~b ALE_TBLWx registers 1 - Table write operation is performed. This will take the current contents from the ~b ALE_TBLWx registers and write them to the table at the specified ~b TABLEIDX.
  [9:0] TABLEIDX — The table index is used to determine which lookup table entry is read or written.
0x24 CPSW_NUSS_VBUSP_MR_LP_NP_RX_REG ro
  [15:0] MR_LP_NP_RX — Link Partner Next Page Received
0x24 CPSW_NUSS_VBUSP_USER_INT_MASKED_REG
  [1:0] USERINTMASKED — User interrupt masked
0x24 CPSW_NUSS_VBUSP_PCSR_CTL_REG
  [1] SIGNAL_OK_EN — PCSR Signal OK Enable
  [0] SIGNAL_OK — PCSR Signal OK
0x24 CPSW_NUSS_VBUSP_GAP_THRESH_REG reset 0xB
  [4:0] GAP_THRESH — Short Gap Threshold
0x24 CPSW_NUSS_VBUSP_P0_RX_MAXLEN_REG reset 0x5EE
  [13:0] RX_MAXLEN — Rx Maximum Frame Length
0x24 CPSW_NUSS_VBUSP_PN_RX_MAXLEN_REG reset 0x5EE
  [13:0] RX_MAXLEN — Rx Maximum Frame Length
0x24 CPSW_NUSS_VBUSP_PN_RX_MAXLEN_REG reset 0x5EE
  [13:0] RX_MAXLEN — Rx Maximum Frame Length
0x24 CPSW_NUSS_VBUSP_PN_RX_MAXLEN_REG reset 0x5EE
  [13:0] RX_MAXLEN — Rx Maximum Frame Length
0x24 CPSW_NUSS_VBUSP_PN_RX_MAXLEN_REG reset 0x5EE
  [13:0] RX_MAXLEN — Rx Maximum Frame Length
0x24 CPSW_NUSS_VBUSP_PN_RX_MAXLEN_REG reset 0x5EE
  [13:0] RX_MAXLEN — Rx Maximum Frame Length
0x24 CPSW_NUSS_VBUSP_PN_RX_MAXLEN_REG reset 0x5EE
  [13:0] RX_MAXLEN — Rx Maximum Frame Length
0x24 CPSW_NUSS_VBUSP_PN_RX_MAXLEN_REG reset 0x5EE
  [13:0] RX_MAXLEN — Rx Maximum Frame Length
0x24 CPSW_NUSS_VBUSP_PN_RX_MAXLEN_REG reset 0x5EE
  [13:0] RX_MAXLEN — Rx Maximum Frame Length
0x24 CPSW_NUSS_VBUSP_RXFRAGMENTS
  [31:0] COUNT — Total number of fragmented frames received
0x24 CPSW_NUSS_VBUSP_INTSTAT_MASKED_REG ro
  [0] TS_PEND — TS_PEND masked interrupt read (after enable)
0x28 CPSW_NUSS_VBUSP_USER_INT_MASK_SET_REG
  [1:0] USERINTMASKSET — MDIO user interrupt mask set
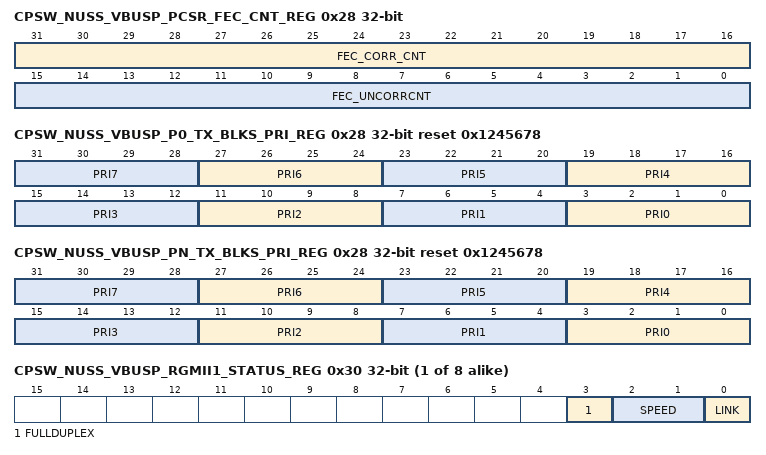
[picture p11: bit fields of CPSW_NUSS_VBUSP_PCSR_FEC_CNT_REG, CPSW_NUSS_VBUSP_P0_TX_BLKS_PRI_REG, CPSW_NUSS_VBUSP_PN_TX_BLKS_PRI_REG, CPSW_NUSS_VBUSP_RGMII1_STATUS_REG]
0x28 CPSW_NUSS_VBUSP_PCSR_FEC_CNT_REG access not given
  [31:16] FEC_CORR_CNT — PCSR FEC Corrected Error Count (access R/WC)
  [15:0] FEC_UNCORRCNT — PCSR FEC Uncorrected Error Count (access R/WC)
0x28 CPSW_NUSS_VBUSP_TX_START_WDS_REG reset 0x8
  [10:0] TX_START_WDS — FIFO Packet Transmit Start Words
0x28 CPSW_NUSS_VBUSP_P0_TX_BLKS_PRI_REG reset 0x1245678
  [4n+3:4n] PRI{n} (n=0..7) — Priority {n} Port Transmit Blocks
0x28 CPSW_NUSS_VBUSP_PN_TX_BLKS_PRI_REG reset 0x1245678
  [4n+3:4n] PRI{n} (n=0..7) — Priority {n} Port Transmit Blocks
0x28 CPSW_NUSS_VBUSP_PN_TX_BLKS_PRI_REG reset 0x1245678
  [4n+3:4n] PRI{n} (n=0..7) — Priority {n} Port Transmit Blocks
0x28 CPSW_NUSS_VBUSP_PN_TX_BLKS_PRI_REG reset 0x1245678
  [4n+3:4n] PRI{n} (n=0..7) — Priority {n} Port Transmit Blocks
0x28 CPSW_NUSS_VBUSP_PN_TX_BLKS_PRI_REG reset 0x1245678
  [4n+3:4n] PRI{n} (n=0..7) — Priority {n} Port Transmit Blocks
0x28 CPSW_NUSS_VBUSP_PN_TX_BLKS_PRI_REG reset 0x1245678
  [4n+3:4n] PRI{n} (n=0..7) — Priority {n} Port Transmit Blocks
0x28 CPSW_NUSS_VBUSP_PN_TX_BLKS_PRI_REG reset 0x1245678
  [4n+3:4n] PRI{n} (n=0..7) — Priority {n} Port Transmit Blocks
0x28 CPSW_NUSS_VBUSP_PN_TX_BLKS_PRI_REG reset 0x1245678
  [4n+3:4n] PRI{n} (n=0..7) — Priority {n} Port Transmit Blocks
0x28 CPSW_NUSS_VBUSP_PN_TX_BLKS_PRI_REG reset 0x1245678
  [4n+3:4n] PRI{n} (n=0..7) — Priority {n} Port Transmit Blocks
0x28 CPSW_NUSS_VBUSP_ALE_DROP
  [31:0] COUNT — Total number of frames dropped by the ALE
0x28 CPSW_NUSS_VBUSP_INT_ENABLE_REG
  [0] TS_PEND_EN — TS_PEND masked interrupt enable
0x2C CPSW_NUSS_VBUSP_USER_INT_MASK_CLEAR_REG
  [1:0] USERINTMASKCLR — MDIO user interrupt mask clear
0x2C CPSW_NUSS_VBUSP_PCSR_ERROR_FIFO_REG access not given
  [0] ERROR_FIFO_CTC — PCSR Error FIFO CTC (access R/WC)
0x2C CPSW_NUSS_VBUSP_EEE_PRESCALE_REG
  [11:0] EEE_PRESCALE — Energy Efficient Ethernet Pre-scale count load value
0x2C CPSW_NUSS_VBUSP_ALE_OVERRUN_DROP
  [31:0] COUNT — Total number of overrun frames dropped by the ALE
0x2C CPSW_NUSS_VBUSP_TS_COMP_NUDGE_REG
  [7:0] NUDGE — This 2s complement number is added to the ts_comp_length value to increase or decrease the TS_COMP length by the nudge amount
{0x2C+4i} CPSW_NUSS_VBUSP_RGMII{i}_STATUS_REG ro (i=1..8)
  [3] FULLDUPLEX — Rgmii{i} full dulex: 0=Half-duplex, 1=Full-duplex
  [2:1] SPEED — Rgmii{i} speed: 00=10Mbps, 01=100Mbps, 10=1000Mbps, 11=reserved
  [0] LINK — Rgmii{i} link indicator: 0=Link is down, 1=Link is up
0x30 CPSW_NUSS_VBUSP_TX_CFG_REG
  [31:0] TX_CFG — Transmit configuration register output
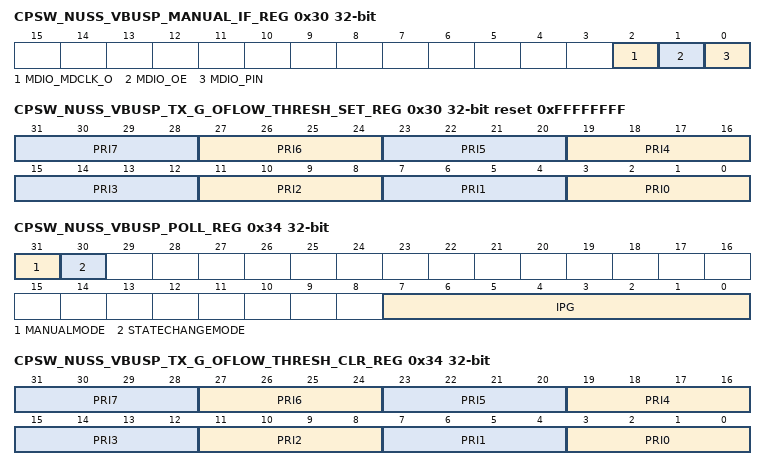
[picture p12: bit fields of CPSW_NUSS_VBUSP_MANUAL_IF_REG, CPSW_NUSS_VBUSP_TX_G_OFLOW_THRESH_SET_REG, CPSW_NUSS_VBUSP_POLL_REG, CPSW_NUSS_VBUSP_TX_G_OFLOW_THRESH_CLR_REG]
0x30 CPSW_NUSS_VBUSP_MANUAL_IF_REG
  [2] MDIO_MDCLK_O — MDIO Clock Output
  [1] MDIO_OE — MDIO Output Enable
  [0] MDIO_PIN
0x30 CPSW_NUSS_VBUSP_TX_G_OFLOW_THRESH_SET_REG reset 0xFFFFFFFF
  [4n+3:4n] PRI{n} (n=0..7) — Priority Based Flow Control Global Outflow Usage Threshold for Pri {n}
0x30 CPSW_NUSS_VBUSP_P0_IDLE2LPI_REG
  [23:0] COUNT — Port 0 EEE Idle to LPI counter load value
0x30 CPSW_NUSS_VBUSP_PN_IDLE2LPI_REG
  [23:0] COUNT — EEE Idle to LPI counter load value
0x30 CPSW_NUSS_VBUSP_PN_IDLE2LPI_REG
  [23:0] COUNT — EEE Idle to LPI counter load value
0x30 CPSW_NUSS_VBUSP_PN_IDLE2LPI_REG
  [23:0] COUNT — EEE Idle to LPI counter load value
0x30 CPSW_NUSS_VBUSP_PN_IDLE2LPI_REG
  [23:0] COUNT — EEE Idle to LPI counter load value
0x30 CPSW_NUSS_VBUSP_PN_IDLE2LPI_REG
  [23:0] COUNT — EEE Idle to LPI counter load value
0x30 CPSW_NUSS_VBUSP_PN_IDLE2LPI_REG
  [23:0] COUNT — EEE Idle to LPI counter load value
0x30 CPSW_NUSS_VBUSP_PN_IDLE2LPI_REG
  [23:0] COUNT — EEE Idle to LPI counter load value
0x30 CPSW_NUSS_VBUSP_PN_IDLE2LPI_REG
  [23:0] COUNT — EEE Idle to LPI counter load value
0x30 CPSW_NUSS_VBUSP_RXOCTETS
  [31:0] COUNT — Total number of received bytes in good frames
0x30 CPSW_NUSS_VBUSP_EVENT_POP_REG wo
  [0] EVENT_POP
0x34 CPSW_NUSS_VBUSP_RX_CFG_REG
  [31:0] RX_CFG — Receive configuration register output
0x34 CPSW_NUSS_VBUSP_POLL_REG
  [31] MANUALMODE — MDIO Manual Mode
  [30] STATECHANGEMODE — MDIO State Change Mode
  [7:0] IPG — MDIO IPG
0x34 CPSW_NUSS_VBUSP_TX_G_OFLOW_THRESH_CLR_REG
  fields as CPSW_NUSS_VBUSP_TX_G_OFLOW_THRESH_SET_REG
